AUTOSAR XML (schema 00051)
package /Components
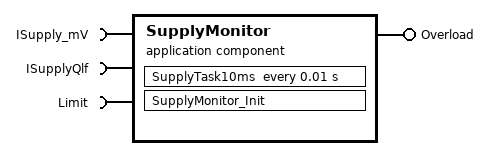
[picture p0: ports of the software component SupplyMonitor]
  application sw component type SupplyMonitor
    require port ISupply_mV: nonqueued-receiver-com-spec{data-element=ISupply_mV, init-value=0}, required-interface=ISupply_mV
    require port ISupplyQlf: nonqueued-receiver-com-spec{data-element=ISupplyQlf, init-value=0}, required-interface=ISupplyQlf
    require port Limit: nonqueued-receiver-com-spec{data-element=Limit, init-value=0}, required-interface=Limit
    provide port Overload: nonqueued-sender-com-spec{data-element=Overload, init-value=0}, provided-interface=Overload
    behavior SupplyMonitor_IB: handle-termination-and-restart=NO-SUPPORT
      timing event Event_SupplyTask10ms: start-on-event=SupplyTask10ms, period=0.01
      runnable SupplyMonitor_Init
      runnable SupplyTask10ms
        data-send-points:
          access OUT_Overload_Overload: accessed-variable=Overload.Overload
